# LPC11E6x register map
File version: 0.8
CPU: CM0PLUS r0p1, little endian, no MPU, no FPU, 0x2 interrupt priority bits, 0x0 interrupts
Registers are 32-bit, read-write, reset 0x0 unless marked. A register's access mark holds for its fields unless they carry their own. Offsets are from the block's base; [hi:lo] are bit positions; lines under a group give offsets from that group; {n}, {i} and the like mark numbered series; 'fields as' and 'values as' point back to an identical list.

## IOCON — I/O control (IOCON)
Base 0x40044000
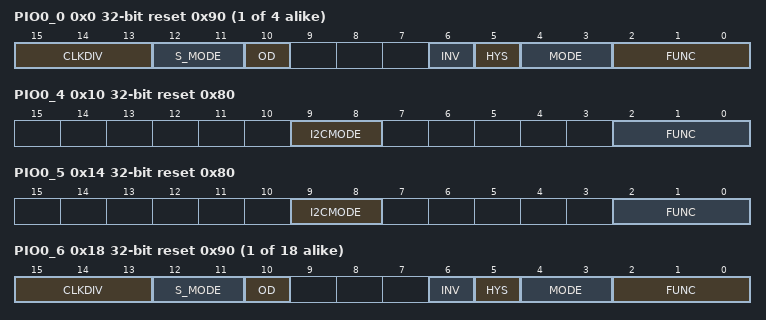
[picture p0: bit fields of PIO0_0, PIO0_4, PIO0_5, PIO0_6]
{0x0+4i} PIO0_{i} reset 0x90 (i=0..3) — I/O configuration for port PIO0
  [15:13] CLKDIV — Select peripheral clock divider for input filter sampling clock IOCONCLKDIV. Value 0x7 is reserved.
    0=IOCONCLKDIV0 (IOCONCLKDIV0. Use IOCON clock divider 0.); 1=IOCONCLKDIV1 (IOCONCLKDIV1. Use IOCON clock divider 1.); 2=IOCONCLKDIV2 (IOCONCLKDIV2 Use IOCON clock divider 2.); {v}=IOCONCLKDIV{v} (IOCONCLKDIV{v}. Use IOCON clock divider {v}.) (v=3..6)
  [12:11] S_MODE — Digital filter sample mode.
    0=BYPASS_INPUT_FILTER; 1=1_CLOCK_CYCLE (1 clock cycle. Input pulses shorter than one filter clock are rejected.); 2=2_CLOCK_CYCLES (2 clock cycles. Input pulses shorter than two filter clocks are rejected.); 3=3_CLOCK_CYCLES (3 clock cycles. Input pulses shorter than three filter clocks are rejected.)
  [10] OD — Open-drain mode.
    0=DISABLE; 1=ENABLE (Enable. Open-drain mode enabled. This is not a true open-drain mode.)
  [6] INV — Invert input
    0=INPUT_NOT_INVERTED (Input not inverted (HIGH on pin reads as 1; LOW on pin reads as 0).); 1=INPUT_INVERTED_HIGH (Input inverted (HIGH on pin reads as 0, LOW on pin reads as 1).)
  [5] HYS — Hysteresis.
    0=DISABLE; 1=ENABLE
  [4:3] MODE — Selects function mode (on-chip pull-up/pull-down resistor control).
    0=INACTIVE_NO_PULL_DO (Inactive (no pull-down/pull-up resistor enabled).); 1=PULL_DOWN_RESISTOR_E (Pull-down resistor enabled.); 2=PULL_UP_RESISTOR_ENA (Pull-up resistor enabled.); 3=REPEATER_MODE
  [2:0] FUNC — Selects pin function.
0x10 PIO0_4 reset 0x80 — I/O configuration for open-drain pin PIO0_4
  [9:8] I2CMODE — Selects I2C mode (see Section 7.3.8). Select Standard mode (I2CMODE = 00, default) or Standard I/O functionality (I2CMODE = 01) if the pin function is GPIO (FUNC = 000).
    0=STANDARD_MODE_FAST (Standard mode/ Fast-mode I2C.); 1=STANDARD_IO_FUNCTIO (Standard I/O functionality); 2=FAST_MODE_PLUS_I2C
  [2:0] FUNC — Selects pin function.
0x14 PIO0_5 reset 0x80 — I/O configuration for open-drain pin PIO0_5
  fields as PIO0_4
{0x0+4i} PIO0_{i} reset 0x90 (i=6..23) — I/O configuration for port PIO0
  fields as PIO0_0
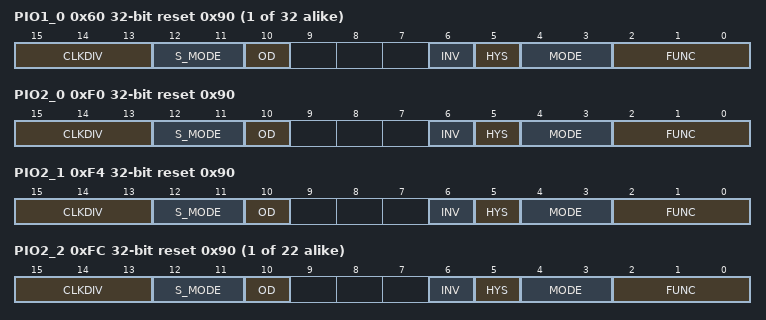
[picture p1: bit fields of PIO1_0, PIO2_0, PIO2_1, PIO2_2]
{0x60+4i} PIO1_{i} reset 0x90 (i=0..31) — I/O configuration for port PIO1
  [15:13] CLKDIV — Select peripheral clock divider for input filter sampling clock IOCONCLKDIV. Value 0x7 is reserved.
    values as PIO0_0.CLKDIV
  [12:11] S_MODE — Digital filter sample mode.
    values as PIO0_0.S_MODE
  [10] OD — Open-drain mode.
    0=DISABLE; 1=ENABLED (Enabled. Open-drain mode enabled. This is not a true open-drain mode.)
  [6] INV — Invert input
    values as PIO0_0.INV
  [5] HYS — Hysteresis.
    0=DISABLE; 1=ENABLE
  [4:3] MODE — Selects function mode (on-chip pull-up/pull-down resistor control).
    values as PIO0_0.MODE
  [2:0] FUNC — Selects pin function.
0xF0 PIO2_0 reset 0x90 — I/O configuration for port PIO2
  fields as PIO1_0
0xF4 PIO2_1 reset 0x90 — I/O configuration for port PIO2
  fields as PIO1_0
{0xF4+4i} PIO2_{i} reset 0x90 (i=2..23) — I/O configuration for port PIO2
  fields as PIO1_0

## GINT0 — GPIO group interrupt 0
Base 0x4005C000
Same registers: GINT1 0x40060000
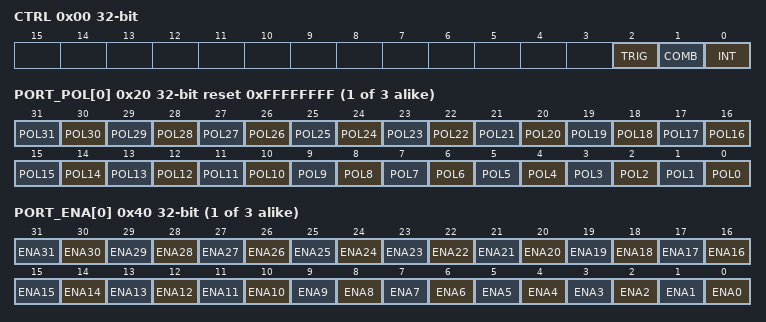
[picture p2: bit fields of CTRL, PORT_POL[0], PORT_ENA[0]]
0x00 CTRL — GPIO grouped interrupt control register
  [2] TRIG — Group interrupt trigger
    0=EDGE_TRIGGERED; 1=LEVEL_TRIGGERED
  [1] COMB — Combine enabled inputs for group interrupt
    0=OR_FUNCTIONALITY_A_ (OR functionality: A grouped interrupt is generated when any one of the enabled inputs is active (based on its programmed polarity).); 1=AND_FUNCTIONALITY_A (AND functionality: An interrupt is generated when all enabled bits are active (based on their programmed polarity).)
  [0] INT — Group interrupt status. This bit is cleared by writing a one to it. Writing zero has no effect.
    0=NO_INTERRUPT_REQUEST (No interrupt request is pending.); 1=INTERRUPT_REQUEST_IS (Interrupt request is active.)
{0x20+4i} PORT_POL[{i}] reset 0xFFFFFFFF (i=0..2) — GPIO grouped interrupt port 0 polarity register
  [n] POL{n} (n=0..31) — Configure pin polarity of port m pins for group interrupt. Bit n corresponds to pin PIOm_n of port m. 0 = the pin is active LOW. If the level on this pin is LOW, the pin contributes to the group interrupt. 1 = the pin is active HIGH. If the level on this pin is HIGH, the pin contributes to the group interrupt.
{0x40+4i} PORT_ENA[{i}] (i=0..2) — GPIO grouped interrupt port enable register
  [n] ENA{n} (n=0..31) — Enable port 0 pin for group interrupt. Bit n corresponds to pin Pm_n of port m. 0 = the port 0 pin is disabled and does not contribute to the grouped interrupt. 1 = the port 0 pin is enabled and contributes to the grouped interrupt.
